# ESP32S3_RADIO register map
File version: 0.1.0
Registers are 32-bit, read-write, no defined reset value unless marked. A register's access mark holds for its fields unless they carry their own. Offsets are from the block's base; [hi:lo] are bit positions; {n}, {i} and the like mark numbered series.

## FE — Front end The FE block, `DR_REG_FE_BASE` 0x60006000: the HAL has the base, no registers.
Base 0x60006000
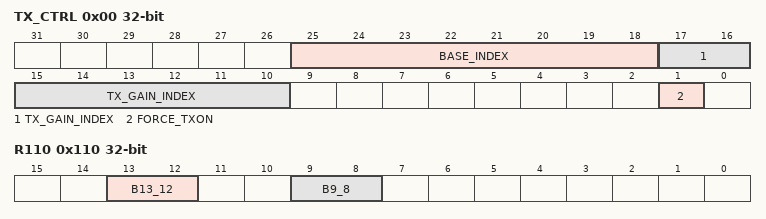
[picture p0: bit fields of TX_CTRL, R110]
0x00 TX_CTRL — Force TX on and the TX gain memory index The library calls `force_txon_mode(1, 0, 0)` and `force_tx_gain()`, which writes gain memory slot 0. That this is the slot the front end then uses holds only while FE_BASE_INDEX reads 0; the code does not check it. Evidence: `lib/esp_sdr/src/esp_sdr_priv.h:164-169` (slot 0)
  [25:18] BASE_INDEX — Base index, read by `force_txon_mode()` and by the tone generator. Evidence: *decompile*
  [17:10] TX_GAIN_INDEX — TX gain memory index (inferred). `force_txon_mode(en, mode, ofs)` writes `(ofs + (mode ? 16 : 0) + bits[25:18]) & 0xff`; the tone generator writes `bits[25:18] + 9`. Evidence: *decompile* S3 `phy_test.o`, `phy_feature.o`
  [1] FORCE_TXON — Force TX on. Without a frame in flight the MAC never enables the transmitter; `force_txon_mode(1, ...)` sets the bit, `(0, ...)` clears it, the vendor tone generator does the same. Without it only a spur near -6 MHz leaks; with it a tone stands 35 to 37 dB over the TX-off noise. Evidence: *measured* bench 2026-10-05; *working* `lib/esp_sdr/src/esp_sdr_tx.c:84-87`, `lib/esp_sdr/src/esp_sdr_rx.c:84-86`; *decompile* S3 `phy_test.o`, `phy_feature.o`
0x100 R100 — Unknown; bits 18:16 listed by upstream's filter probe
  [18:16] B18_16 ro — Unknown; listed by upstream's filter probe. Could not be written from the shell (`devmem`). Evidence: *measured* bench 2026-10-06; *speculative* `modules/lib/esp-sdr/main/diagnostics/filter_probe.h:19-20`
0x110 R110 — Unknown; written by `force_txon_mode()` and `bt_rx_force(0)`
  [13:12] B13_12 — 3 when `force_txon_mode()`'s mode is not 0, else 0. Evidence: *decompile* S3 `phy_test.o`
  [9:8] B9_8 — Stepped 0x200, 0x300, 0 (2, 3 and 0 in the field) by `bt_rx_force(0)`, which `force_rx_gain(force, index, 0)` calls (see AGC_FORCE_REG). Evidence: *decompile* S3 `phy_test.o`
0x140 IQ_EST_CONF0 — IQ estimator configuration; lead, not tried The vendor's `ram_iq_est_enable()` configures the IQ estimator in FE_IQ_EST_CONF0_REG and FE_IQ_EST_CONF1_REG (count up to 0x7fff); its done flag is FE_IQ_EST_DONE. It gives power, DC and a quadrature correlation against the transmit tone generator, work it could take off the CPU. Evidence: *decompile* S3 `libphy.a`
0x144 IQ_EST_CONF1 — IQ estimator configuration; lead, not tried Configured together with FE_IQ_EST_CONF0_REG; see there. Evidence: *decompile* S3 `libphy.a`
0x174 R174 — IQ estimator done flag; lead, not tried
  [16] IQ_EST_DONE ro — Done flag of the IQ estimator (see FE_IQ_EST_CONF0_REG). Evidence: *decompile* S3 `libphy.a`

## BB — Baseband Leads, none tried: a spur notch and CCA busy counters that could take work off the CPU.
Base 0x6001D000
0x14 SPUR_NOTCH0 — Spur notch; lead, not tried The spur notch is at BB_SPUR_NOTCH0_REG and BB_SPUR_NOTCH1_REG. Evidence: *decompile* S3 `libphy.a`
0x18 SPUR_NOTCH1 — Spur notch; lead, not tried See BB_SPUR_NOTCH0_REG. Evidence: *decompile* S3 `libphy.a`
{0x58+4i} CCA_BUSY_CNT{i} (i=0..2) ro — CCA busy counters; lead, not tried With AGC_RSSI, candidates for 802.15.4 energy detection and CCA. Evidence: *decompile* S3 `libphy.a`

## RTC_CNTL — USB PHY select
Base 0x60008000
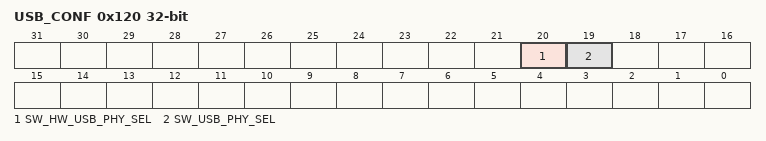
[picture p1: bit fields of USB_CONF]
0x120 USB_CONF — USB PHY select; documented, descriptions empty Other bits: documented 18:0 The OTG driver sets both fields and they survive a software reset; the consequence is in hardware-quirks.md, "Building and flashing". Evidence: `modules/hal/espressif/components/soc/esp32s3/register/soc/rtc_cntl_reg.h:3071-3083`; mapping in `modules/hal/espressif/components/esp_hal_usb/esp32s3/include/hal/usb_wrap_ll.h:55-66` Evidence: *measured*, bench 2026-10-09 (survive a software reset)
  [20] SW_HW_USB_PHY_SEL — 1: software drives the USB PHY mux.
  [19] SW_USB_PHY_SEL — 1: internal PHY to USB OTG. 0: to USB-Serial-JTAG.
